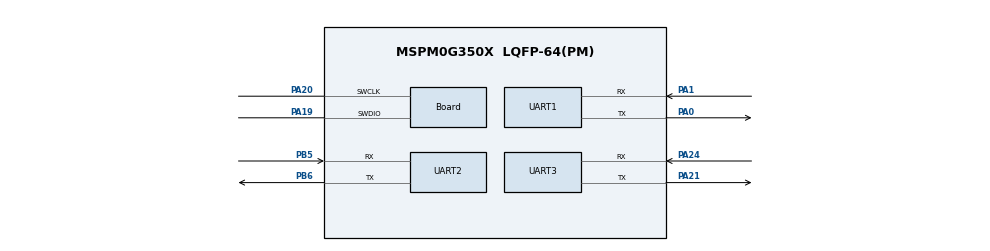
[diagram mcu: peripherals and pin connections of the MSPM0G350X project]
/**
 * @cliArgs --device "MSPM0G350X" --part "Default" --package "LQFP-64(PM)" --product "mspm0_sdk@2.05.01.00"
 * @versions {"tool":"1.24.1+4189"}
 */

/**
 * Import the modules used in this configuration.
 */
const SYSCTL        = scripting.addModule("/ti/driverlib/SYSCTL");
const SYSTICK       = scripting.addModule("/ti/driverlib/SYSTICK");
const TIMER         = scripting.addModule("/ti/driverlib/TIMER", {}, false);
const TIMER1        = TIMER.addInstance();
const UART          = scripting.addModule("/ti/driverlib/UART", {}, false);
const UART1         = UART.addInstance();
const UART2         = UART.addInstance();
const UART3         = UART.addInstance();
const ProjectConfig = scripting.addModule("/ti/project_config/ProjectConfig");

/**
 * Write custom configuration values to the imported modules.
 */
SYSCTL.forceDefaultClkConfig = true;
SYSCTL.clockTreeEn           = true;

const Board                       = scripting.addModule("/ti/driverlib/Board", {}, false);
Board.peripheral.$assign          = "DEBUGSS";
Board.peripheral.swclkPin.$assign = "PA20";
Board.peripheral.swdioPin.$assign = "PA19";

SYSTICK.periodEnable    = true;
SYSTICK.period          = 32000;
SYSTICK.systickEnable   = true;
SYSTICK.interruptEnable = true;

TIMER1.$name              = "TIMER_0";
TIMER1.timerMode          = "PERIODIC";
TIMER1.interrupts         = ["ZERO"];
TIMER1.interruptPriority  = "1";
TIMER1.timerClkDiv        = 4;
TIMER1.timerStartTimer    = true;
TIMER1.timerClkPrescale   = 256;
TIMER1.timerPeriod        = "50 ms";
TIMER1.peripheral.$assign = "TIMA0";

UART1.enabledInterrupts                = ["RX"];
UART1.$name                            = "SCREEN";
UART1.peripheral.$assign               = "UART0";
UART1.peripheral.rxPin.$assign         = "PA1";
UART1.peripheral.txPin.$assign         = "PA0";
UART1.txPinConfig.$name                = "ti_driverlib_gpio_GPIOPinGeneric0";
UART1.txPinConfig.direction            = scripting.forceWrite("OUTPUT");
UART1.txPinConfig.hideOutputInversion  = scripting.forceWrite(false);
UART1.txPinConfig.onlyInternalResistor = scripting.forceWrite(false);
UART1.txPinConfig.passedPeripheralType = scripting.forceWrite("Digital");
UART1.rxPinConfig.$name                = "ti_driverlib_gpio_GPIOPinGeneric1";
UART1.rxPinConfig.hideOutputInversion  = scripting.forceWrite(false);
UART1.rxPinConfig.onlyInternalResistor = scripting.forceWrite(false);
UART1.rxPinConfig.passedPeripheralType = scripting.forceWrite("Digital");

UART2.$name                            = "MOTOR";
UART2.targetBaudRate                   = 115200;
UART2.peripheral.$assign               = "UART1";
UART2.peripheral.rxPin.$assign         = "PB5";
UART2.peripheral.txPin.$assign         = "PB6";
UART2.txPinConfig.$name                = "ti_driverlib_gpio_GPIOPinGeneric2";
UART2.txPinConfig.direction            = scripting.forceWrite("OUTPUT");
UART2.txPinConfig.hideOutputInversion  = scripting.forceWrite(false);
UART2.txPinConfig.onlyInternalResistor = scripting.forceWrite(false);
UART2.txPinConfig.passedPeripheralType = scripting.forceWrite("Digital");
UART2.rxPinConfig.$name                = "ti_driverlib_gpio_GPIOPinGeneric3";
UART2.rxPinConfig.hideOutputInversion  = scripting.forceWrite(false);
UART2.rxPinConfig.onlyInternalResistor = scripting.forceWrite(false);
UART2.rxPinConfig.passedPeripheralType = scripting.forceWrite("Digital");

UART3.$name                            = "K230";
UART3.targetBaudRate                   = 115200;
UART3.enabledInterrupts                = ["RX"];
UART3.peripheral.$assign               = "UART2";
UART3.peripheral.rxPin.$assign         = "PA24";
UART3.peripheral.txPin.$assign         = "PA21";
UART3.txPinConfig.$name                = "ti_driverlib_gpio_GPIOPinGeneric4";
UART3.txPinConfig.direction            = scripting.forceWrite("OUTPUT");
UART3.txPinConfig.hideOutputInversion  = scripting.forceWrite(false);
UART3.txPinConfig.onlyInternalResistor = scripting.forceWrite(false);
UART3.txPinConfig.passedPeripheralType = scripting.forceWrite("Digital");
UART3.rxPinConfig.$name                = "ti_driverlib_gpio_GPIOPinGeneric5";
UART3.rxPinConfig.hideOutputInversion  = scripting.forceWrite(false);
UART3.rxPinConfig.onlyInternalResistor = scripting.forceWrite(false);
UART3.rxPinConfig.passedPeripheralType = scripting.forceWrite("Digital");

ProjectConfig.genStartup         = false;
ProjectConfig.genLinker          = false;
ProjectConfig.genOpts            = false;
ProjectConfig.genLibs            = false;
ProjectConfig.migrationCondition = true;
